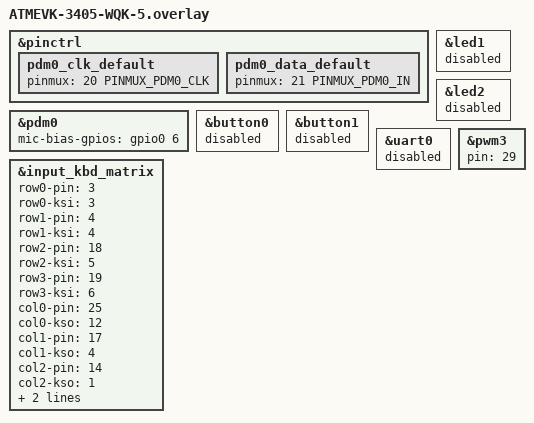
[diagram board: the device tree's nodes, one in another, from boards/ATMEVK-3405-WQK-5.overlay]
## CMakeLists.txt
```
# Copyright (c) 2026 Atmosic
#
# SPDX-License-Identifier: LicenseRef-Atmosic

cmake_minimum_required(VERSION 3.20.0)
set(EXTRA_DTC_OVERLAY_FILE "app.overlay")

find_package(Zephyr REQUIRED HINTS $ENV{ZEPHYR_BASE})
project(hid_remote)

include_directories(
  src
  src/bt
)

target_sources(app PRIVATE
  src/main.c
  src/rc_mmi.c
  src/rc_mmi_timer.c
  src/rc_input.c
  src/bt/rc_gap.c
  src/bt/rc_hids.c
)

if(CONFIG_RC_VOICE)
  target_sources(app PRIVATE src/rc_audio.c)
endif()

if(CONFIG_RC_LED)
  target_sources(app PRIVATE src/rc_led.c)
endif()

if(CONFIG_IR_NEC)
  target_sources(app PRIVATE src/rc_ir.c)
endif()

if(CONFIG_BT_IAS)
  target_sources(app PRIVATE src/rc_fmp.c)
endif()
```

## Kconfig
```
# Copyright (c) 2026 Atmosic
#
# SPDX-License-Identifier: LicenseRef-Atmosic

module = HID_REMOTE
module-str = hid_remote
source "subsys/logging/Kconfig.template.log_config"

config RC_VOICE
	bool "RC voice pipeline (ATVV + optional DMIC)"
	select ATM_ATVV
	select AUDIO
	select AUDIO_DMIC
	select AUDIO_ADPCM_ENC
	imply DMIC_ATM
	help
	  Enable the ATVV BLE voice profile with IMA ADPCM encoding.
	  DMIC_ATM is implied (not selected) because it has a devicetree
	  dependency (DT_HAS_ATMOSIC_ATM_PDM_ENABLED) that is satisfied by
	  the pdm0 node enabled in app.overlay under CONFIG_RC_VOICE.

if RC_VOICE

choice RC_ATVV_ASST_MODEL
	prompt "Assistant interaction model"
	default RC_ATVV_ASST_MODEL_ON_REQUEST
	help
	  Selects which "Assistant" button interaction model this remote
	  implements (Google Voice over BLE spec 1.0 §4.5). PTT/HTT require
	  CONFIG_ATVV_SPEC_V1_0 — v0.4e only defines On-request.

config RC_ATVV_ASST_MODEL_ON_REQUEST
	bool "On-request (legacy) — host decides when to open the mic"
	help
	  Mandatory baseline model, supported by all remotes. Mic button
	  press sends START_SEARCH; the host decides whether to open the
	  microphone via MIC_OPEN.

config RC_ATVV_ASST_MODEL_PTT
	bool "Press-to-Talk"
	depends on ATVV_SPEC_V1_0
	help
	  The remote opens the mic (AUDIO_START, reason=PTT) on Assistant
	  button press without waiting for MIC_OPEN. This implementation
	  closes it (AUDIO_STOP, reason=OTHER) on button release, since a
	  single button offers no separate "stop" gesture and the spec does
	  not define a dedicated reason code for a locally-initiated PTT
	  stop. The host may still end the session early via MIC_CLOSE.

config RC_ATVV_ASST_MODEL_HTT
	bool "Hold-to-Talk"
	depends on ATVV_SPEC_V1_0
	help
	  The remote opens the mic (AUDIO_START, reason=HTT) while the
	  Assistant button is held and closes it (AUDIO_STOP,
	  reason=HTT_RELEASE) on release, without waiting for MIC_OPEN, per
	  spec v1.0 §4.5.3. The host may still end the session early via
	  MIC_CLOSE.

endchoice

choice RC_ATVV_AUDIO_RATE
	prompt "Preferred ATVV audio sample rate"
	default RC_ATVV_AUDIO_RATE_16KHZ if ATVV_SPEC_V1_0
	default RC_ATVV_AUDIO_RATE_8KHZ
	depends on RC_VOICE
	help
	  Selects the sample rate and codec used when starting an ATVV audio
	  stream. The v1.0 capability response advertises both ADPCM 8 kHz and
	  16 kHz.

config RC_ATVV_AUDIO_RATE_8KHZ
	bool "8 kHz ADPCM"

config RC_ATVV_AUDIO_RATE_16KHZ
	bool "16 kHz ADPCM"
	depends on ATVV_SPEC_V1_0

endchoice

config RC_PDM_DEBUG
	bool "PDM-only debug mode"
	depends on RC_VOICE
	help
	  Debug mode for testing the PDM → ADPCM pipeline. When enabled,
	  pressing the key at row 0, col 1 in IDLE state starts audio
	  streaming directly (bypassing ATVV). Pressing the same key again
	  stops streaming and returns to IDLE.

choice LOG_MODE
	default LOG_MODE_IMMEDIATE if RC_PDM_DEBUG
endchoice

endif # RC_VOICE

config RC_LED
	bool "RC LED status indicator"
	default y if $(dt_alias_enabled,led0)
	depends on GPIO
	help
	  Enable LED blink patterns for pairing, reconnecting, and FMP alert
	  indication. Requires a ``led0`` GPIO alias in the board devicetree.
	  A build-time assertion will fire if this option is enabled but the
	  alias is absent.

config RC_IDLE_TIMEOUT_CS
	int "Idle disconnect timeout (centiseconds)"
	default 60000
	help
	  Disconnect after this many centiseconds of BLE inactivity while HID
	  is ready. Default 60000 cs = 600 s (10 minutes).

config RC_READY_TIMEOUT_CS
	int "HID ready watchdog timeout (centiseconds)"
	default 3000
	help
	  If HID does not become ready within this time after connection,
	  the connection is dropped. Default 3000 cs = 30 s.

config RC_HIB_DELAY_CS
	int "Hibernate delay after MMI idle (centiseconds)"
	default 1000
	help
	  Delay before entering hibernate once the MMI reaches idle state.
	  Default 1000 cs = 10 s.

config RC_AUDIO_STREAM_TIMEOUT_CS
	int "Audio Transfer Timeout (centiseconds)"
	default 3000
	depends on RC_VOICE
	help
	  Maximum duration of a single ATVV audio stream, per spec v1.0 §4.6.1
	  "Audio Transfer Timeout" (recommended 15-60 seconds). When this timeout
	  expires, the remote sends AUDIO_STOP (reason=TIMEOUT) and stops
	  streaming to prevent battery drain if the host fails to send MIC_CLOSE.
	  The host can extend the session by sending MIC_EXTEND (v1.0) before
	  expiry. Default 3000 cs = 30 s.

config RC_ADV_INTERVAL_MIN
	hex "Advertising interval minimum (units of 625 us)"
	default 0x0040
	help
	  Minimum advertising interval. Default 0x0040 = 40 ms.

config RC_ADV_INTERVAL_MAX
	hex "Advertising interval maximum (units of 625 us)"
	default 0x0040
	help
	  Maximum advertising interval. Default 0x0040 = 40 ms.

config RC_ADV0_DURATION_MS
	int "Reconnect advertising duration (ms)"
	default 30000
	help
	  Duration of the reconnect advertising window.

config RC_ADV1_DURATION_MS
	int "Pairing advertising duration (ms)"
	default 30000
	help
	  Duration of undirected pairing advertising window. Default 30000 ms.

source "Kconfig.zephyr"
```

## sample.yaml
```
# Copyright (c) 2026 Atmosic
#
# SPDX-License-Identifier: LicenseRef-Atmosic

sample:
  description: BLE HID Remote Controller sample
  name: BLE HID Remote Controller sample
common:
  sysbuild: true
  harness: console
  harness_config:
    type: one_line
    regex:
      - "rc_gap: Advertising Start"
  tags:
    - bluetooth
    - hid_remote
  depends_on:
    - hid_remote
tests:
  applications.hid_remote.atm: {}
  applications.hid_remote.atm.mcuboot.ota:
    tags:
      - mcuboot
    extra_args:
      - SB_CONFIG_BOOTLOADER_MCUBOOT=y
      - SB_CONFIG_BOOT_SIGNATURE_TYPE_ECDSA_P256=y
      - SB_CONFIG_MCUBOOT_MODE_SWAP_SCRATCH=y
      - SB_ATM_DTS_EXTRA_CPPFLAGS="-DATM_MCUBOOT_SWAP_WITH_OFFSET=0"
      - EXTRA_CONF_FILE="basic_ota_bt.conf"
```

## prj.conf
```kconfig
# Copyright (c) 2026 Atmosic
#
# SPDX-License-Identifier: LicenseRef-Atmosic

# BT core
CONFIG_BT=y
CONFIG_BT_SMP=y
CONFIG_BT_PERIPHERAL=y
CONFIG_BT_EXT_ADV=y
CONFIG_BT_EXT_ADV_MAX_ADV_SET=3
CONFIG_BT_ID_MAX=1
CONFIG_BT_MAX_PAIRED=2
CONFIG_BT_MAX_CONN=3
CONFIG_BT_KEYS_OVERWRITE_OLDEST=y

# Hibernation-retained pairing-mode marker
CONFIG_RETAINED_MEM=y

# Enable GATT client so the peripheral can initiate an MTU exchange when the
# host supports it. ATVV v1.0 sends one 128-byte notification per audio frame.
CONFIG_BT_GATT_CLIENT=y
CONFIG_BT_L2CAP_TX_MTU=146
CONFIG_BT_BUF_ACL_TX_SIZE=146
CONFIG_BT_BUF_ACL_RX_SIZE=146
CONFIG_BT_BUF_ACL_TX_COUNT=10
CONFIG_BT_ATT_TX_COUNT=20
CONFIG_BT_BUF_EVT_RX_COUNT=11
CONFIG_RC_PDM_DEBUG=n
CONFIG_ATM_DMIC_CAPTURE_ON_RISING=y

# Connection parameter preferences
CONFIG_BT_PERIPHERAL_PREF_MIN_INT=6
CONFIG_BT_PERIPHERAL_PREF_MAX_INT=12
CONFIG_BT_PERIPHERAL_PREF_LATENCY=99
CONFIG_BT_PERIPHERAL_PREF_TIMEOUT=400

# DIS
CONFIG_BT_DIS=y
CONFIG_BT_DIS_PNP=y
CONFIG_BT_DIS_MANUF_NAME_STR="Atmosic Tech."
CONFIG_BT_DIS_PNP_VID_SRC=2
CONFIG_BT_DIS_PNP_VID=0x045E
CONFIG_BT_DIS_PNP_PID=0x0050
CONFIG_BT_DIS_PNP_VER=0x0100

# BAS
CONFIG_BT_BAS=y

# Device identity
CONFIG_BT_DEVICE_NAME="Atmosic RC"
CONFIG_BT_DEVICE_APPEARANCE=384

# Stack sizes
CONFIG_MAIN_STACK_SIZE=2048
CONFIG_SYSTEM_WORKQUEUE_STACK_SIZE=2048
CONFIG_STACK_SENTINEL=y

# Settings / NVS
CONFIG_BT_SETTINGS=y
CONFIG_SETTINGS=y
CONFIG_NVS=y
CONFIG_FLASH=y
CONFIG_FLASH_MAP=y
CONFIG_FLASH_PAGE_LAYOUT=y

# Input subsystem
CONFIG_INPUT=y

# SMF (MMI + GAP state machine)
CONFIG_SMF=y

# Vendor API commands
CONFIG_ATM_VENDOR_API=y
CONFIG_VND_API_SET_ADV_TX_POWER=y
CONFIG_VND_API_SET_CON_TX_POWER=y

# HOGP
CONFIG_ATM_HOGP=y

# FMP — Find Me Profile
CONFIG_BT_IAS=y

# VOICE / AUDIO
CONFIG_RC_VOICE=y

# IR/NEC blaster
CONFIG_IR_NEC=y

# Log
CONFIG_LOG=y
```

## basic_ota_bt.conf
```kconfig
# Copyright (c) 2026 Atmosic
#
# SPDX-License-Identifier: LicenseRef-Atmosic

# Enable MCUmgr with image and OS management command groups
CONFIG_ATM_MCUMGR=y

# Enable MCUmgr Bluetooth transport with encryption (level 2)
CONFIG_MCUMGR_TRANSPORT_BT=y
CONFIG_MCUMGR_TRANSPORT_BT_PERM_RW_ENCRYPT=y
```

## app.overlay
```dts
/*
 * Copyright (c) 2026 Atmosic
 *
 * SPDX-License-Identifier: LicenseRef-Atmosic
 */

&wdog0 {
	status = "okay";
};

&pwm3 {
	status = "okay";
};

/ {
	ir_blaster: ir_blaster {
		compatible = "atmosic,ir-nec";
		pwms = <&pwm3 3 0 0>;
	};
};

&pdm0 {
	status = "okay";
	pinctrl-0 = <&pdm0_clk_default &pdm0_data_default>;
	pinctrl-names = "default";
	clock-frequency = <1000000>;
};
```

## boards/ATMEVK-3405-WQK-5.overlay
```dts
/*
 * Copyright (c) 2022-2026 Atmosic
 *
 * SPDX-License-Identifier: LicenseRef-Atmosic
 */

&pinctrl {
	pdm0_clk_default: pdm0_clk_default {
		pinmux = <20 PINMUX_PDM0_CLK>;
	};

	pdm0_data_default: pdm0_data_default {
		pinmux = <21 PINMUX_PDM0_IN>;
	};
};

&pdm0 {
	/* P6 is freed by disabling the board LED below. */
	mic-bias-gpios = <&gpio0 6 GPIO_ACTIVE_HIGH>;
};

&led1 {
	status = "disabled";
};

&led2 {
	status = "disabled";
};

&button0 {
	status = "disabled";
};

&button1 {
	status = "disabled";
};

&uart0 {
	status = "disabled";
};

&pwm3 {
	pin = <29>;
};

&input_kbd_matrix {
	row0-pin = <3>;
	row0-ksi = <3>;
	row1-pin = <4>;
	row1-ksi = <4>;
	row2-pin = <18>;
	row2-ksi = <5>;
	row3-pin = <19>;
	row3-ksi = <6>;
	col0-pin = <25>;
	col0-kso = <12>;
	col1-pin = <17>;
	col1-kso = <4>;
	col2-pin = <14>;
	col2-kso = <1>;
	col3-pin = <22>;
	col3-kso = <9>;
	status = "okay";
};
```

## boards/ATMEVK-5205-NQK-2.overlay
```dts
/*
 * Copyright (c) 2026 Atmosic
 *
 * SPDX-License-Identifier: LicenseRef-Atmosic
 */

&pinctrl {
	pdm0_clk_default: pdm0_clk_default {
		pinmux = <30 PINMUX_PDM0_CLK>;
	};

	pdm0_data_default: pdm0_data_default {
		pinmux = <13 PINMUX_PDM0_IN>;
	};
};

&pdm0 {
	mic-bias-gpios = <&gpio2 9 GPIO_ACTIVE_HIGH>;
};

&input_kbd_matrix {
	row0-pin = <26>;
	row0-ksi = <0>;
	row1-pin = <39>;
	row1-ksi = <8>;
	row2-pin = <37>;
	row2-ksi = <6>;
	row3-pin = <38>;
	row3-ksi = <7>;
	col0-pin = <14>;
	col0-kso = <1>;
	col1-pin = <15>;
	col1-kso = <2>;
	col2-pin = <16>;
	col2-kso = <3>;
	col3-pin = <17>;
	col3-kso = <4>;
	status = "okay";
};
```

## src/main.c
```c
/*
 * Copyright (c) 2026 Atmosic
 *
 * SPDX-License-Identifier: LicenseRef-Atmosic
 */

#include <zephyr/kernel.h>
#include <zephyr/drivers/watchdog.h>
#include <zephyr/logging/log.h>
#include <zephyr/pm/pm.h>

#include "rc_mmi.h"

LOG_MODULE_REGISTER(main, CONFIG_HID_REMOTE_LOG_LEVEL);

#define SLEEP_TIME        K_SECONDS(3)
#define WDT_MIN_WINDOW_MS 0
#define WDT_MAX_WINDOW_MS 5000
#define WDT_FEED_INTERVAL K_SECONDS(2)

struct device const *wdog_dev = DEVICE_DT_GET(DT_ALIAS(watchdog0));
static int wdt_channel_id;

/*
 * Feed the watchdog periodically, independent of PM state transitions. While
 * connected (e.g. during pairing) the SoC can stay awake for longer than the
 * watchdog window with no PM transition, so relying on PM notifiers alone
 * starves the watchdog and triggers a spurious SoC reset mid-pairing.
 */
static void wdog_feed_work_handler(struct k_work *work)
{
	struct k_work_delayable *dwork = k_work_delayable_from_work(work);

	wdt_feed(wdog_dev, wdt_channel_id);
	k_work_reschedule(dwork, WDT_FEED_INTERVAL);
}

static K_WORK_DELAYABLE_DEFINE(wdog_feed_work, wdog_feed_work_handler);

#ifdef CONFIG_PM
static void wdog_poke(enum pm_state state)
{
	wdt_feed(wdog_dev, wdt_channel_id);
}

static struct pm_notifier notifier = {
	.state_entry = wdog_poke,
	.state_exit = wdog_poke,
};
#endif

int main(void)
{
	struct wdt_timeout_cfg wdt_config = {
		.flags = WDT_FLAG_RESET_SOC,
		.window.min = WDT_MIN_WINDOW_MS,
		.window.max = WDT_MAX_WINDOW_MS,
		.callback = NULL,
	};

	wdt_channel_id = wdt_install_timeout(wdog_dev, &wdt_config);
	if (wdt_channel_id < 0) {
		LOG_ERR("Watchdog install error: %d", wdt_channel_id);
		return 1;
	}

	int ret = wdt_setup(wdog_dev, 0);
	if (ret < 0) {
		LOG_ERR("Watchdog setup error: %d", ret);
		return 1;
	}

	rc_mmi_init();

	/* Keep feeding the watchdog while awake, regardless of PM activity. */
	k_work_reschedule(&wdog_feed_work, WDT_FEED_INTERVAL);

#ifdef CONFIG_PM
	pm_notifier_register(&notifier);
#else
	while (true) {
		k_sleep(SLEEP_TIME);
		wdt_feed(wdog_dev, wdt_channel_id);
	}
#endif

	return 0;
}
```

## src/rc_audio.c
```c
/*
 * Copyright (c) 2026 Atmosic
 *
 * SPDX-License-Identifier: LicenseRef-Atmosic
 */

#include "rc_audio.h"
#include "rc_mmi.h"
#include "atvv.h"

#include <zephyr/kernel.h>
#include <zephyr/logging/log.h>
#include <zephyr/logging/log_ctrl.h>
#include <zephyr/sys/byteorder.h>
#include <zephyr/settings/settings.h>

#if defined(CONFIG_DMIC_ATM)
#include "adpcm_enc.h"
#include <zephyr/audio/dmic.h>
#endif

LOG_MODULE_REGISTER(rc_audio, CONFIG_HID_REMOTE_LOG_LEVEL);

#define RC_ATVV_SETTINGS_KEY "atvv/cfg"

static bool atvv_configured;

#if defined(CONFIG_DMIC_ATM)
/* DMIC to ADPCM to ATVV streaming pipeline. */
/* The PDM block contains 32 samples; one ATVV frame contains 256 samples. */
#define PP_BUFFER_WORDS 16
#define PP_SAMPLES      (PP_BUFFER_WORDS * 2)
#if defined(CONFIG_RC_ATVV_AUDIO_RATE_16KHZ)
#define AUDIO_SAMPLE_RATE 16000
#else
#define AUDIO_SAMPLE_RATE 8000
#endif
#define PCM_WIDTH_BITS        16
#define BLOCK_SIZE            (PP_SAMPLES * sizeof(int16_t)) /* 64 bytes */
#define PCM_SAMPLES_PER_FRAME (ATVV_AUDIO_DATA_SIZE * 2)
#define NUM_SLAB_BLOCKS       ((PCM_SAMPLES_PER_FRAME + PP_SAMPLES - 1) / PP_SAMPLES + 4)

K_MEM_SLAB_DEFINE_STATIC(audio_slab, BLOCK_SIZE, NUM_SLAB_BLOCKS, 4);

static const struct device *dmic_dev = DEVICE_DT_GET(DT_NODELABEL(pdm0));

static volatile bool streaming_active;
static uint16_t frame_seq;
static struct k_sem stream_sem;

#define AUDIO_STACK_SIZE 2048
static K_THREAD_STACK_DEFINE(audio_stack, AUDIO_STACK_SIZE);
static struct k_thread audio_tid;

/* Send AUDIO_SYNC periodically, including frame 0. */
#define SYNC_PERIOD_FRAMES 20

#ifdef CONFIG_RC_PDM_DEBUG
/* Optional debug capture buffers. */
#define PDM_DBG_DUMP_FRAMES 125
static int16_t pdm_dbg_pcm[PDM_DBG_DUMP_FRAMES * PCM_SAMPLES_PER_FRAME];
static uint8_t pdm_dbg_adpcm[PDM_DBG_DUMP_FRAMES * ATVV_AUDIO_DATA_SIZE];
static uint32_t pdm_dbg_frame_cnt;
#endif
#endif /* CONFIG_DMIC_ATM */

static int atvv_cfg_set(const char *key, size_t len, settings_read_cb read_cb, void *cb_arg)
{
	ARG_UNUSED(key);
	if (len != sizeof(atvv_configured)) {
		return -EINVAL;
	}
	int rc = read_cb(cb_arg, &atvv_configured, sizeof(atvv_configured));
	return rc < 0 ? rc : 0;
}

SETTINGS_STATIC_HANDLER_DEFINE(rc_atvv, "atvv", NULL, atvv_cfg_set, NULL, NULL);

static void atvv_save_configured(bool configured)
{
	atvv_configured = configured;
	settings_save_one(RC_ATVV_SETTINGS_KEY, &atvv_configured, sizeof(atvv_configured));
}

/* ATVV callbacks. */

#if defined(CONFIG_ATVV_SPEC_V1_0)

#if defined(CONFIG_RC_ATVV_AUDIO_RATE_16KHZ)
#define RC_ATVV_CODEC_USED ATVV_CODEC_ADPCM_16K
#else
#define RC_ATVV_CODEC_USED ATVV_CODEC_ADPCM_8K
#endif
#define RC_ATVV_CODECS_SUPPORTED ATVV_CODEC_ADPCM_8K_16K

/* Assistant interaction model reported in CAPS_RESP. */
#if defined(CONFIG_RC_ATVV_ASST_MODEL_HTT)
#define RC_ATVV_MODEL ATVV_ASST_MODEL_HTT
#elif defined(CONFIG_RC_ATVV_ASST_MODEL_PTT)
#define RC_ATVV_MODEL ATVV_ASST_MODEL_PTT
#else /* CONFIG_RC_ATVV_ASST_MODEL_ON_REQUEST */
#define RC_ATVV_MODEL ATVV_ASST_MODEL_ON_REQUEST
#endif

/* Current ATVV stream ID. */
static uint8_t current_stream_id;
/* True while an ATVV audio session is active. */
static bool session_active;

#if defined(CONFIG_RC_ATVV_ASST_MODEL_PTT) || defined(CONFIG_RC_ATVV_ASST_MODEL_HTT)
/* Allocate PTT/HTT stream IDs. */
static uint8_t alloc_stream_id(void)
{
	static uint8_t next_id = 0x01;
	uint8_t id = next_id;

	next_id = (next_id >= 0x80) ? 0x01 : (uint8_t)(next_id + 1);
	return id;
}
#endif

#endif /* CONFIG_ATVV_SPEC_V1_0 */

/* Audio transfer timeout. */

static void audio_timeout_handler(struct k_work *work);
static K_WORK_DELAYABLE_DEFINE(audio_timeout_work, audio_timeout_handler);

/* Start or reset the audio timeout. */
static void audio_timeout_start(void)
{
	k_work_reschedule(&audio_timeout_work, K_MSEC(CONFIG_RC_AUDIO_STREAM_TIMEOUT_CS * 10));
	LOG_DBG("Audio Transfer Timeout started/reset (%u cs)", CONFIG_RC_AUDIO_STREAM_TIMEOUT_CS);
}

static void audio_timeout_stop(void)
{
	k_work_cancel_delayable(&audio_timeout_work);
}

static void audio_timeout_handler(struct k_work *work)
{
	LOG_WRN("Audio Transfer Timeout expired — stopping stream");
	rc_audio_stream_stop();
	rc_mmi_run_event(MMI_OP_CLOSE_MIC);
#if defined(CONFIG_ATVV_SPEC_V1_0)
	atvv_send_audio_stop(ATVV_AUDIO_STOP_REASON_TIMEOUT);
	session_active = false;
#else
	atvv_send_audio_stop();
#endif
}

static void atvv_tx_recv_cb(uint8_t cmd, uint8_t const *data, uint16_t len)
{
	switch (cmd) {
	case ATVV_TX_GET_CAPS:
		/* Host requests capabilities — respond with CAPS_RESP */
		LOG_INF("GET_CAPS");
#if defined(CONFIG_ATVV_SPEC_V1_0)
		const struct atvv_caps_resp_params caps = {
			.version = ATVV_VERSION_V1_0,
			.codecs = RC_ATVV_CODECS_SUPPORTED,
			.asst_model = RC_ATVV_MODEL,
			.frame_size = ATVV_FRAME_SIZE,
		};
#else
		const struct atvv_caps_resp_params caps = {
			.version = ATVV_VERSION_V0_4,
			.codecs = ATVV_CODEC_ADPCM_8K,
			.asst_model = 0,
			.frame_size = ATVV_FRAME_SIZE,
		};
#endif
		atvv_send_caps_resp(&caps);
		atvv_save_configured(true);
		break;
	case ATVV_TX_MIC_OPEN: {
#if defined(CONFIG_ATVV_SPEC_V1_0)
		if (atvv_get_state() != ATVV_STATE_READY || len != 1) {
			LOG_WRN("MIC_OPEN ignored: state=%d len=%u", atvv_get_state(), len);
			break;
		}

		/* v1.0 MIC_OPEN contains mic_mode; the codec comes from configuration. */
		uint8_t mic_mode = (len >= 1) ? data[0] : ATVV_MIC_MODE_PLAYBACK;

		LOG_INF("MIC_OPEN mic_mode=0x%02x codec=0x%02x", mic_mode,
			(unsigned)RC_ATVV_CODEC_USED);

		if (session_active) {
			if (current_stream_id != ATVV_STREAM_ID_MIC_OPEN) {
				LOG_WRN("MIC_OPEN rejected: PTT/HTT stream ongoing");
				atvv_send_mic_open_error(ATVV_ERR_PTT_HTT_ONGOING);
			} else {
				LOG_DBG("MIC_OPEN ignored: stream already active");
			}
			break;
		}
		current_stream_id = ATVV_STREAM_ID_MIC_OPEN;
		session_active = true;
		atvv_send_audio_start(ATVV_AUDIO_START_REASON_MIC_OPEN, RC_ATVV_CODEC_USED,
				      current_stream_id);
		audio_timeout_start();
#else
		if (atvv_get_state() != ATVV_STATE_READY || len != 2) {
			LOG_WRN("MIC_OPEN ignored: state=%d len=%u", atvv_get_state(), len);
			break;
		}

		/* v0.4e MIC_OPEN payload: codec_used(2, big-endian) */
		uint16_t codec_used = (len >= 2) ? sys_get_be16(data) : ATVV_CODEC_ADPCM_8K;

		LOG_INF("MIC_OPEN codec=0x%04x", codec_used);
		if (codec_used != ATVV_CODEC_ADPCM_8K) {
			LOG_WRN("Unsupported codec 0x%04x", codec_used);
			atvv_send_mic_open_error(ATVV_ERR_INVALID_CODEC);
			break;
		}
		atvv_send_audio_start();
		audio_timeout_start();
#endif
		rc_mmi_run_event(MMI_OP_OPEN_MIC);
		break;
	}
	case ATVV_TX_MIC_CLOSE:
#if defined(CONFIG_ATVV_SPEC_V1_0)
	{
		if (!session_active) {
			LOG_DBG("MIC_CLOSE ignored: no active session");
			break;
		}

		/* v1.0 MIC_CLOSE contains the stream ID. */
		uint8_t req_id = (len >= 1) ? data[0] : ATVV_STREAM_ID_ANY;

		LOG_INF("MIC_CLOSE stream_id=0x%02x (active=0x%02x)", req_id, current_stream_id);
		if (req_id != ATVV_STREAM_ID_ANY && req_id != current_stream_id) {
			LOG_DBG("MIC_CLOSE stream_id mismatch — ignored");
			break;
		}
		audio_timeout_stop();
		rc_audio_stream_stop();
		atvv_send_audio_stop(ATVV_AUDIO_STOP_REASON_MIC_CLOSE);
		session_active = false;
	}
#else
		LOG_INF("MIC_CLOSE");
		audio_timeout_stop();
		rc_audio_stream_stop();
		atvv_send_audio_stop();
#endif
		rc_mmi_run_event(MMI_OP_CLOSE_MIC);
		break;
#if defined(CONFIG_ATVV_SPEC_V1_0)
	case ATVV_TX_MIC_EXTEND:
		/* Keep the audio timeout alive. */
		LOG_DBG("MIC_EXTEND stream_id=0x%02x", (len >= 1) ? data[0] : 0xFF);
		if (session_active) {
			audio_timeout_start(); /* reset the timer */
		}
		break;
#endif
	default:
		LOG_DBG("ATVV TX cmd 0x%02x (unhandled)", cmd);
		break;
	}
}

static void atvv_state_changed_cb(atvv_state_t state)
{
	LOG_INF("ATVV state -> %d", state);
	switch (state) {
	case ATVV_STATE_READY:
		rc_mmi_run_event(MMI_OP_ATVV_READY);
		break;
	case ATVV_STATE_IDLE:
#if defined(CONFIG_ATVV_SPEC_V1_0)
		audio_timeout_stop();
		session_active = false;
		current_stream_id = ATVV_STREAM_ID_MIC_OPEN;
#endif
		atvv_save_configured(false);
		rc_mmi_run_event(MMI_OP_ATVV_UNREADY);
		break;
	case ATVV_STATE_ENABLED:
		rc_mmi_run_event(MMI_OP_ATVV_UNREADY);
		break;
	}
}

static atvv_cb_t const atvv_cbs = {
	.tx_recv = atvv_tx_recv_cb,
	.state_changed = atvv_state_changed_cb,
};

bool rc_audio_atvv_was_configured(void)
{
	return atvv_configured;
}

#if defined(CONFIG_DMIC_ATM)
static void audio_thread_fn(void *p1, void *p2, void *p3)
{
	static int16_t pcm_acc[PCM_SAMPLES_PER_FRAME];
	static int16_t block_pcm[PP_SAMPLES];
	size_t pcm_samples = 0;
	bool mtu_error = false;

	/* Reset the encoder at the start of each session. */
	adpcm_reset();

#ifdef CONFIG_RC_PDM_DEBUG
	pdm_dbg_frame_cnt = 0;
#endif

	while (streaming_active) {
		void *buf = NULL;
		size_t size = 0;
		int ret = dmic_read(dmic_dev, 0, &buf, &size, 200);
		if (ret) {
			if (ret != -EAGAIN) {
				LOG_ERR("dmic_read err %d", ret);
			}
			continue;
		}

		size_t sample_count = MIN(size / sizeof(int16_t), ARRAY_SIZE(block_pcm));
		memcpy(block_pcm, buf, sample_count * sizeof(int16_t));
		k_mem_slab_free(&audio_slab, buf);

		for (size_t i = 0; i < sample_count; i++) {
			pcm_acc[pcm_samples++] = block_pcm[i];
			if (pcm_samples < PCM_SAMPLES_PER_FRAME) {
				continue;
			}

			/* Capture the encoder state before this frame. */
			struct atvv_audio_frame frame = {};
			uint8_t predictor_idx = 0;
			int32_t predictor_val = adpcm_get_index(&predictor_idx);
			uint16_t this_frame_no = frame_seq;
			bool need_sync = (this_frame_no % SYNC_PERIOD_FRAMES) == 0;

			/* Encode one frame. */
			adpcm_encode_buf(pcm_acc, frame.val, PCM_SAMPLES_PER_FRAME);
			frame_seq++;

#ifdef CONFIG_RC_PDM_DEBUG
			if (pdm_dbg_frame_cnt < PDM_DBG_DUMP_FRAMES) {
				memcpy(&pdm_dbg_pcm[pdm_dbg_frame_cnt * PCM_SAMPLES_PER_FRAME],
				       pcm_acc, PCM_SAMPLES_PER_FRAME * sizeof(int16_t));
				memcpy(&pdm_dbg_adpcm[pdm_dbg_frame_cnt * ATVV_AUDIO_DATA_SIZE],
				       frame.val, ATVV_AUDIO_DATA_SIZE);
				pdm_dbg_frame_cnt++;
			}
#endif

			/* Continue remaining samples in the next frame. */
			pcm_samples = 0;

#if defined(CONFIG_ATVV_SPEC_V1_0)
			/* v1.0 sends state in periodic AUDIO_SYNC messages. */
			if (need_sync) {
				/* Count logical audio notifications. */
				uint16_t notify_seq = this_frame_no * ATVV_AUDIO_NOTIFY_COUNT;
				int sync_ret =
					atvv_send_audio_sync(RC_ATVV_CODEC_USED, notify_seq,
							     (int16_t)predictor_val, predictor_idx);
				if (sync_ret) {
					LOG_WRN("ATVV AUDIO_SYNC failed: %d, seq=%u", sync_ret,
						notify_seq);
				}
			}
			int send_ret = atvv_send_audio_frame(&frame);
			if (send_ret == -EMSGSIZE) {
				LOG_ERR("ATVV audio stopped: insufficient ATT MTU");
				streaming_active = false;
				mtu_error = true;
			} else if (send_ret) {
				LOG_WRN("ATVV audio packet dropped (%d), frame=%u", send_ret,
					this_frame_no);
			}
#else
			/* v0.4e carries state in the frame header. */
			frame.idx = predictor_idx;
			frame.prevp = sys_cpu_to_be16((int16_t)predictor_val);
			frame.seqn = sys_cpu_to_be16(this_frame_no);
			frame.padding = 0x00;

			int send_ret = atvv_send_audio_frame(&frame);
			if (send_ret == -EMSGSIZE) {
				LOG_ERR("ATVV audio stopped: insufficient ATT MTU");
				streaming_active = false;
				mtu_error = true;
			} else if (send_ret) {
				LOG_DBG("ATVV send dropped (%d)", send_ret);
			}
			if (need_sync) {
				atvv_send_audio_sync(this_frame_no);
			}
#endif
		}
	}

	dmic_trigger(dmic_dev, DMIC_TRIGGER_STOP);
	LOG_INF("audio thread stopped");
	if (mtu_error) {
#if defined(CONFIG_ATVV_SPEC_V1_0)
		atvv_send_audio_stop(ATVV_AUDIO_STOP_REASON_OTHER);
#else
		atvv_send_audio_stop();
#endif
		rc_mmi_run_event(MMI_OP_CLOSE_MIC);
	}

#ifdef CONFIG_RC_PDM_DEBUG
	/* Serialize optional debug output. */
	LOG_PANIC();
	LOG_INF("=== PDM DBG dump: %u frames ===", pdm_dbg_frame_cnt);
	for (uint32_t i = 0; i < pdm_dbg_frame_cnt; i++) {
		LOG_HEXDUMP_INF(&pdm_dbg_pcm[i * PCM_SAMPLES_PER_FRAME],
				PCM_SAMPLES_PER_FRAME * sizeof(int16_t), "PCM");
	}
	LOG_INF("=== PDM DBG dump end ===");
	LOG_INF("=== ADPCM DBG dump: %u frames, %u bytes/frame ===", pdm_dbg_frame_cnt,
		ATVV_AUDIO_DATA_SIZE);
	for (uint32_t i = 0; i < pdm_dbg_frame_cnt; i++) {
		LOG_HEXDUMP_INF(&pdm_dbg_adpcm[i * ATVV_AUDIO_DATA_SIZE], ATVV_AUDIO_DATA_SIZE,
				"ADPCM");
	}
	LOG_INF("=== ADPCM DBG dump end ===");
#endif
}

static int dmic_start_capture(void)
{
	struct pcm_stream_cfg stream = {
		.pcm_rate = AUDIO_SAMPLE_RATE,
		.pcm_width = PCM_WIDTH_BITS,
		.block_size = BLOCK_SIZE,
		.mem_slab = &audio_slab,
	};
	struct dmic_cfg cfg = {
		.io =
			{
				.min_pdm_clk_freq = 1000000,
				.max_pdm_clk_freq = 4000000,
				.min_pdm_clk_dc = 40,
				.max_pdm_clk_dc = 60,
			},
		.streams = &stream,
		.channel =
			{
				.req_num_chan = 1,
				.req_num_streams = 1,
			},
	};

	int ret = dmic_configure(dmic_dev, &cfg);
	if (ret) {
		LOG_ERR("dmic_configure err %d", ret);
		return ret;
	}

	ret = dmic_trigger(dmic_dev, DMIC_TRIGGER_START);
	if (ret) {
		LOG_ERR("dmic_trigger START err %d", ret);
	}
	return ret;
}

#endif /* CONFIG_DMIC_ATM */

/* ── Public API ──────────────────────────────────────────────────────────── */

void rc_audio_init(void)
{
	settings_load_subtree("atvv");
	LOG_INF("ATVV prev configured: %d", atvv_configured);
	atvv_init(&atvv_cbs);
#if defined(CONFIG_DMIC_ATM)
	if (!device_is_ready(dmic_dev)) {
		LOG_ERR("DMIC device not ready");
		return;
	}
	k_sem_init(&stream_sem, 0, 1);
	LOG_INF("rc_audio init: DMIC+ATVV ready");
#else
	LOG_INF("rc_audio init: ATVV only (no DMIC)");
#endif
}

void rc_audio_stream_start(void)
{
#if defined(CONFIG_DMIC_ATM)
	if (streaming_active) {
		return;
	}
	frame_seq = 0;
	streaming_active = true;

	int ret = dmic_start_capture();
	if (ret) {
		streaming_active = false;
		rc_mmi_run_event(MMI_OP_CLOSE_MIC);
		return;
	}

	k_thread_create(&audio_tid, audio_stack, K_THREAD_STACK_SIZEOF(audio_stack),
			audio_thread_fn, NULL, NULL, NULL, K_PRIO_PREEMPT(7), 0, K_NO_WAIT);
	k_thread_name_set(&audio_tid, "rc_audio");
	LOG_INF("audio stream started");
#else
	LOG_INF("rc_audio_stream_start: DMIC not enabled");
#endif
}

void rc_audio_stream_stop(void)
{
#if defined(CONFIG_DMIC_ATM)
	if (!streaming_active) {
		return;
	}
	streaming_active = false;
	/* audio_thread_fn checks streaming_active and will call dmic_trigger(STOP) */
	LOG_INF("audio stream stop requested");
#endif
}

void rc_audio_start_search(void)
{
	if (atvv_get_state() != ATVV_STATE_READY) {
		LOG_WRN("ATVV not ready, ignoring start_search");
		return;
	}

#if defined(CONFIG_RC_ATVV_ASST_MODEL_PTT) || defined(CONFIG_RC_ATVV_ASST_MODEL_HTT)
	/* PTT/HTT: remote unilaterally opens the mic on button press,
	 * without waiting for a host MIC_OPEN (v1.0 §4.5.2 / §4.5.3). */
	if (session_active) {
		LOG_DBG("start_search: session already active");
		return;
	}
	current_stream_id = alloc_stream_id();
	session_active = true;
#if defined(CONFIG_RC_ATVV_ASST_MODEL_HTT)
	atvv_send_audio_start(ATVV_AUDIO_START_REASON_HTT, RC_ATVV_CODEC_USED, current_stream_id);
#else
	atvv_send_audio_start(ATVV_AUDIO_START_REASON_PTT, RC_ATVV_CODEC_USED, current_stream_id);
#endif
	audio_timeout_start();
	LOG_INF("PTT/HTT stream opened (stream_id=0x%02x)", current_stream_id);
	rc_mmi_run_event(MMI_OP_OPEN_MIC);
#else
	/* On-request (mandatory baseline): remote sends START_SEARCH on mic
	 * button press. Host responds with MIC_OPEN to begin streaming. */
	LOG_INF("START_SEARCH");
	atvv_send_ctl(ATVV_CTL_SEARCH_START, NULL, 0);
#endif
}

void rc_audio_stop_search(void)
{
#if defined(CONFIG_RC_ATVV_ASST_MODEL_PTT)
	/* PTT: stop the locally initiated stream on button release. */
	if (!session_active) {
		return;
	}
	audio_timeout_stop();
	rc_audio_stream_stop();
	rc_mmi_run_event(MMI_OP_CLOSE_MIC);
	atvv_send_audio_stop(ATVV_AUDIO_STOP_REASON_OTHER);
	session_active = false;
	LOG_INF("PTT release stopped");
#elif defined(CONFIG_RC_ATVV_ASST_MODEL_HTT)
	/* HTT: button release stops the stream immediately, remote-initiated
	 * (v1.0 §4.5.3), without waiting for MIC_CLOSE. */
	if (!session_active) {
		return;
	}
	audio_timeout_stop();
	rc_audio_stream_stop();
	rc_mmi_run_event(MMI_OP_CLOSE_MIC);
	atvv_send_audio_stop(ATVV_AUDIO_STOP_REASON_HTT_RELEASE);
	session_active = false;
	LOG_INF("HTT release stopped");
#else
	/* On-request: button-initiated stop mirrors a host-driven MIC_CLOSE
	 * from the remote's own release of the mic key. */
	audio_timeout_stop();
	rc_audio_stream_stop();
	rc_mmi_run_event(MMI_OP_CLOSE_MIC);
#if defined(CONFIG_ATVV_SPEC_V1_0)
	atvv_send_audio_stop(ATVV_AUDIO_STOP_REASON_MIC_CLOSE);
	session_active = false;
	current_stream_id = ATVV_STREAM_ID_MIC_OPEN;
#else
	atvv_send_audio_stop();
#endif
	LOG_INF("search stopped");
#endif
}

void rc_audio_dpad_select(void)
{
	atvv_state_t s = atvv_get_state();

	if (s == ATVV_STATE_READY || s == ATVV_STATE_ENABLED) {
		LOG_DBG("DPAD_SELECT");
		atvv_send_ctl(ATVV_CTL_DPAD_SELECT, NULL, 0);
	}
}
```

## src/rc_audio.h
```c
/*
 * Copyright (c) 2026 Atmosic
 *
 * SPDX-License-Identifier: LicenseRef-Atmosic
 */

#pragma once

#include <stdbool.h>

/** @brief Initialise the audio subsystem (ATVV + optional DMIC). */
void rc_audio_init(void);

/** @brief Start the audio capture and streaming pipeline. */
void rc_audio_stream_start(void);

/** @brief Stop the audio capture and streaming pipeline. */
void rc_audio_stream_stop(void);

/**
 * @brief Start voice search / streaming on Assistant (MIC) button press.
 *
 * Behaviour depends on CONFIG_RC_ATVV_ASST_MODEL:
 *   - On-request : sends ATVV_CTL_SEARCH_START; host replies with MIC_OPEN.
 *   - PTT / HTT  : remote itself sends AUDIO_START and begins streaming,
 *                  without waiting for MIC_OPEN (requires CONFIG_ATVV_SPEC_V1_0).
 * No-op if ATVV is not ready, or if a session is already active.
 */
void rc_audio_start_search(void);

/**
 * @brief Returns true if ATVV was successfully configured in a previous session.
 *
 * Persisted via Settings subsystem.
 * Use to skip CAPS negotiation on reconnect when host is known to support ATVV.
 */
bool rc_audio_atvv_was_configured(void);

/**
 * @brief Stop voice search on Assistant (MIC) button release.
 *
 * Behaviour depends on CONFIG_RC_ATVV_ASST_MODEL:
 *   - On-request : stops local capture and sends AUDIO_STOP (reason
 *                  ATVV_AUDIO_STOP_REASON_MIC_CLOSE on CONFIG_ATVV_SPEC_V1_0;
 *                  no payload on CONFIG_ATVV_SPEC_V0_4).
 *   - HTT        : stops local capture and sends AUDIO_STOP (reason
 *                  ATVV_AUDIO_STOP_REASON_HTT_RELEASE) immediately.
 *   - PTT        : stops local capture and sends AUDIO_STOP (reason
 *                  ATVV_AUDIO_STOP_REASON_OTHER) on button release.
 */
void rc_audio_stop_search(void);

/**
 * @brief Notify host of a D-pad select (OK button) during voice session.
 *
 * Sends ATVV_CTL_DPAD_SELECT to the host. Should be called on OK key press
 * when ATVV is in READY or streaming state.
 */
void rc_audio_dpad_select(void);
```

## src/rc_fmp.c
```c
/*
 * Copyright (c) 2026 Atmosic
 *
 * SPDX-License-Identifier: LicenseRef-Atmosic
 */

#include <zephyr/bluetooth/services/ias.h>
#include <zephyr/logging/log.h>

#include "rc_fmp.h"
#include "rc_led.h"

LOG_MODULE_REGISTER(rc_fmp, CONFIG_HID_REMOTE_LOG_LEVEL);

/* ── IAS callbacks ──────────────────────────────────────────────────────── */

static void rc_fmp_no_alert(void)
{
	LOG_INF("FMP: no alert");
	rc_led_set(RC_LED_OFF);
}

static void rc_fmp_mild_alert(void)
{
	LOG_INF("FMP: mild alert");
	rc_led_set(RC_LED_FMP_MILD);
}

static void rc_fmp_high_alert(void)
{
	LOG_INF("FMP: high alert");
	rc_led_set(RC_LED_FMP_HIGH);
}

BT_IAS_CB_DEFINE(rc_fmp_cb) = {
	.no_alert = rc_fmp_no_alert,
	.mild_alert = rc_fmp_mild_alert,
	.high_alert = rc_fmp_high_alert,
};

/* ── Init ───────────────────────────────────────────────────────────────── */

void rc_fmp_init(void)
{
	LOG_INF("FMP init");
}
```

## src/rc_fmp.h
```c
/*
 * Copyright (c) 2026 Atmosic
 *
 * SPDX-License-Identifier: LicenseRef-Atmosic
 */

#pragma once

/** @brief Initialise the FMP / IAS server. */
void rc_fmp_init(void);
```

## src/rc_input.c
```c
/*
 * Copyright (c) 2026 Atmosic
 *
 * SPDX-License-Identifier: LicenseRef-Atmosic
 */

#include <zephyr/kernel.h>
#include <zephyr/sys/reboot.h>
#include <zephyr/input/input.h>
#include <zephyr/device.h>
#include <zephyr/logging/log.h>

#ifdef CONFIG_PM
#include <zephyr/pm/pm.h>
#include <zephyr/pm/policy.h>
#endif

#include "rc_input.h"
#include "rc_mmi.h"
#include "rc_vkey.h"
#include "bt/rc_gap.h"
#include "bt/rc_hids.h"
#include "rc_led.h"
#ifdef CONFIG_IR_NEC
#include "rc_ir.h"
#endif
#ifdef CONFIG_RC_VOICE
#include "rc_audio.h"
#endif

LOG_MODULE_REGISTER(rc_input, CONFIG_HID_REMOTE_LOG_LEVEL);

#define INPUT_KBD_MATRIX_NODE DT_NODELABEL(input_kbd_matrix)

#define KEY_BUF_SIZE 16
static struct {
	uint8_t row;
	uint8_t col;
	bool pressed;
} keybuf[KEY_BUF_SIZE];
static uint8_t keybuf_offset;
static bool state_reconnected;

/* Key positions from rc_vkey.h consumer_map */
#define COMBO_HOME_ROW 1
#define COMBO_HOME_COL 2
#define COMBO_BACK_ROW 1
#define COMBO_BACK_COL 1
#define COMBO_OK_ROW   2
#define COMBO_OK_COL   0
#define COMBO_VOLU_ROW 2
#define COMBO_VOLU_COL 3

enum combo_id {
	COMBO_PAIRING,  /* HOME + BACK — enter pairing mode */
	COMBO_DEL_BOND, /* OK + VOLU  — delete all bonds    */
	COMBO_NUM,
};

enum combo_key_slot {
	COMBO_KEY_A,
	COMBO_KEY_B,
	COMBO_KEY_COUNT,
};

#define KBD_KEY_ROW_CMP(row, key)       ((row) == (key))
#define KBD_KEY_COLUMN_CMP(column, key) ((column) == (key))
#define KBD_KEY_CMP(row, row_key, column, column_key)                                              \
	(KBD_KEY_ROW_CMP(row, row_key) && KBD_KEY_COLUMN_CMP(column, column_key))

/* Per-combo descriptor */
struct combo_desc {
	uint8_t row_a, col_a;
	uint8_t row_b, col_b;
	const char *name;
};

static const struct combo_desc combo_descs[COMBO_NUM] = {
	[COMBO_PAIRING] = {COMBO_HOME_ROW, COMBO_HOME_COL, COMBO_BACK_ROW, COMBO_BACK_COL,
			   "HOME+BACK"},
	[COMBO_DEL_BOND] = {COMBO_OK_ROW, COMBO_OK_COL, COMBO_VOLU_ROW, COMBO_VOLU_COL, "OK+VOLU"},
};

/* Per-key press state indexed by combo ID and key slot. */
static bool combo_key_state[COMBO_NUM][COMBO_KEY_COUNT];

/* One work item per combo so the action runs outside the input callback. */
static struct k_work_delayable combo_works[COMBO_NUM];
static bool combo_active[COMBO_NUM];

static rc_input_led_restore_cb_t led_restore_cb;

static void combo_action_exec(enum combo_id id)
{
	LOG_INF("Combo %s fired", combo_descs[id].name);
	rc_hogp_send_release_all();

	switch (id) {
	case COMBO_PAIRING:
		LOG_INF("Entering pairing mode until cold boot");
		rc_gap_set_force_pairing();
		return;
	case COMBO_DEL_BOND:
		rc_gap_remove_all_bond();
		break;
	default:
		break;
	}

	rc_led_set(RC_LED_OFF);
	k_sleep(K_MSEC(1000));
	sys_reboot(SYS_REBOOT_COLD);
}

/* Each combo has its own handler to avoid shared-variable race on cancel. */
static void combo_pairing_handler(struct k_work *work)
{
	combo_active[COMBO_PAIRING] = false;
	combo_action_exec(COMBO_PAIRING);
}

static void combo_del_bond_handler(struct k_work *work)
{
	combo_active[COMBO_DEL_BOND] = false;
	combo_action_exec(COMBO_DEL_BOND);
}

static k_work_handler_t const combo_handlers[COMBO_NUM] = {
	[COMBO_PAIRING] = combo_pairing_handler,
	[COMBO_DEL_BOND] = combo_del_bond_handler,
};

/* Returns true when at least one combo is currently active (both keys pressed),
 * meaning the caller should suppress normal HID processing for this key event.
 * A single combo key pressed alone is NOT suppressed — only the combination. */
static bool combo_key_update(uint32_t row, uint32_t col, bool pressed)
{
	/* Update press state for every key that belongs to any combo */
	bool relevant = false;

	for (int i = 0; i < COMBO_NUM; i++) {
		const struct combo_desc *d = &combo_descs[i];

		if (KBD_KEY_CMP(row, d->row_a, col, d->col_a)) {
			combo_key_state[i][COMBO_KEY_A] = pressed;
			relevant = true;
		} else if (KBD_KEY_CMP(row, d->row_b, col, d->col_b)) {
			combo_key_state[i][COMBO_KEY_B] = pressed;
			relevant = true;
		}
	}

	if (!relevant) {
		return false;
	}

	/* Activate / cancel each combo independently */
	bool any_active = false;

	for (int i = 0; i < COMBO_NUM; i++) {
		bool both = combo_key_state[i][COMBO_KEY_A] && combo_key_state[i][COMBO_KEY_B];

		if (!combo_active[i] && both) {
			combo_active[i] = true;
			LOG_INF("Combo detected: %s", combo_descs[i].name);
			k_work_reschedule(&combo_works[i], K_NO_WAIT);
		}

		if (combo_active[i]) {
			any_active = true;
		}
	}

	if (any_active) {
		rc_led_set(RC_LED_ON);
	} else if (led_restore_cb) {
		led_restore_cb();
	} else {
		rc_led_set(RC_LED_OFF);
	}

	/* Suppress HID once a combo is detected. */
	return any_active;
}

static void handle_key_hid_ready(uint32_t row, uint32_t col, bool pressed, int state)
{
	uint16_t csm = rc_vkey_get_consumer_code(row, col);

	if (!csm) {
		rc_hogp_send_key_report(row, col, pressed);
		return;
	}

	rc_hogp_send_consumer_report(pressed ? csm : 0);

#ifdef CONFIG_RC_VOICE
	if (csm == HID_CSM_MIC) {
		if (pressed && state == MMI_S_HID_READY) {
			rc_audio_start_search();
		} else if (!pressed && state == MMI_S_STREAMING) {
			rc_audio_stop_search();
		}
		return;
	}
	if (pressed && csm == HID_CSM_OK) {
		rc_audio_dpad_select();
	}
#endif /* CONFIG_RC_VOICE */
}

void rc_input_handle_key(uint32_t row, uint32_t col, bool pressed)
{
#ifdef CONFIG_IR_NEC
	/* IR is independent of BLE state — send/stop on any key event. */
	uint16_t ir_addr;
	uint8_t ir_cmd;

	if (rc_vkey_get_ir_code(row, col, &ir_addr, &ir_cmd)) {
		pressed ? rc_ir_send(ir_addr, ir_cmd) : rc_ir_stop();
	}
#endif

	/* Combo key detection (pairing / delete bond) — works in all states.
	 * combo_key_update() returns true if this key belongs to an active combo;
	 * in that case suppress the normal HID path so the host never sees
	 * the individual key events while the combo is being held. */
	if (combo_key_update(row, col, pressed)) {
		return;
	}

#if defined(CONFIG_PM) && !defined(CONFIG_APP_BATT)
	if (pressed) {
		pm_policy_state_lock_get(PM_STATE_SOFT_OFF, PM_ALL_SUBSTATES);
	} else {
		if (pm_policy_state_lock_is_active(PM_STATE_SOFT_OFF, PM_ALL_SUBSTATES)) {
			pm_policy_state_lock_put(PM_STATE_SOFT_OFF, PM_ALL_SUBSTATES);
		}
	}
#endif

	int state = rc_mmi_get_state();

#ifdef CONFIG_RC_PDM_DEBUG
	/* Debug: row0/col1 toggles PDM streaming, bypassing ATVV/BLE.
	 * Intercept in all states except DISCONNING to avoid conflict. */
	if (row == 0 && col == 1 && state != MMI_S_DISCONNING) {
		if (pressed) {
			if (state != MMI_S_STREAMING) {
				LOG_INF("DBG: start PDM streaming (from state %d)", state);
				rc_mmi_run_event(MMI_OP_OPEN_MIC);
			} else {
				LOG_INF("DBG: stop PDM streaming");
				rc_mmi_run_event(MMI_OP_CLOSE_MIC);
			}
		}
		return;
	}
#endif

	if (state == MMI_S_IDLE) {
		rc_gap_discoverable(true);
	}

	if (state < MMI_S_HID_READY) {
		uint16_t csm = rc_vkey_get_consumer_code(row, col);

		if (csm == HID_CSM_MIC) {
			return;
		}
		if (keybuf_offset < KEY_BUF_SIZE) {
			keybuf[keybuf_offset].row = (uint8_t)row;
			keybuf[keybuf_offset].col = (uint8_t)col;
			keybuf[keybuf_offset].pressed = pressed;
			keybuf_offset++;
		} else {
			LOG_DBG("keybuf overflow");
		}
		return;
	}

	handle_key_hid_ready(row, col, pressed, state);
}

void rc_input_flush_keybuf(void)
{
	if (!state_reconnected) {
		keybuf_offset = 0;
		return;
	}

	for (uint8_t i = 0; i < keybuf_offset; i++) {
		uint32_t r = keybuf[i].row;
		uint32_t c = keybuf[i].col;
		bool pressed = keybuf[i].pressed;
		uint16_t csm = rc_vkey_get_consumer_code(r, c);

		if (csm) {
			rc_hogp_send_consumer_report(pressed ? csm : 0);
		} else {
			rc_hogp_send_key_report(r, c, pressed);
		}
	}
	state_reconnected = false;
	keybuf_offset = 0;
}

bool rc_input_keybuf_pending(void)
{
	return keybuf_offset > 0;
}

void rc_input_set_reconnected(bool reconnected)
{
	state_reconnected = reconnected;
}

static void input_callback(struct input_event *evt, void *user_data)
{
	static uint32_t row, col;

	switch (evt->code) {
	case INPUT_ABS_X:
		col = evt->value;
		break;
	case INPUT_ABS_Y:
		row = evt->value;
		break;
	case INPUT_BTN_TOUCH:
		if (evt->sync) {
			rc_input_handle_key(row, col, (bool)evt->value);
		}
		break;
	}
}

INPUT_CALLBACK_DEFINE(DEVICE_DT_GET(INPUT_KBD_MATRIX_NODE), input_callback, NULL);

void rc_input_init(rc_input_led_restore_cb_t cb)
{
	led_restore_cb = cb;
	for (int i = 0; i < COMBO_NUM; i++) {
		k_work_init_delayable(&combo_works[i], combo_handlers[i]);
	}
}
```

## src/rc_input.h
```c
/*
 * Copyright (c) 2026 Atmosic
 *
 * SPDX-License-Identifier: LicenseRef-Atmosic
 */

#pragma once

#include <stdint.h>
#include <stdbool.h>

/**
 * @brief Callback to restore the LED to the current MMI-state-appropriate mode.
 *
 * Provided by rc_mmi.c and called by the combo engine when a combo is
 * cancelled so the LED reverts to whatever the state machine dictates.
 */
typedef void (*rc_input_led_restore_cb_t)(void);

/**
 * @brief Initialise the input/combo subsystem.
 *
 * Must be called once after rc_led_init().
 * The INPUT_CALLBACK_DEFINE listener is registered at build time; this call
 * only initialises the combo work items.
 *
 * @param led_restore_cb  Callback invoked when an active combo is cancelled.
 */
void rc_input_init(rc_input_led_restore_cb_t led_restore_cb);

/**
 * @brief Dispatch a decoded key event into the input pipeline.
 *
 * Handles IR, combo detection, PM locks, key buffering, and HID reports.
 * Called from the INPUT_CALLBACK_DEFINE listener inside rc_input.c.
 * Also exposed so rc_mmi.c can replay buffered keys on reconnect without
 * duplicating the HID send logic.
 *
 * @param row      Matrix row of the key.
 * @param col      Matrix column of the key.
 * @param pressed  true = pressed, false = released.
 */
void rc_input_handle_key(uint32_t row, uint32_t col, bool pressed);

/**
 * @brief Flush buffered key events accumulated before HID was ready.
 *
 * Called by rc_mmi.c when transitioning to MMI_S_HID_READY.
 */
void rc_input_flush_keybuf(void);

/**
 * @brief Return true if any buffered keys are pending.
 */
bool rc_input_keybuf_pending(void);

/**
 * @brief Update the "state reconnected" flag used when flushing the keybuf.
 *
 * Set to true on CONNECTED, cleared after flush.
 */
void rc_input_set_reconnected(bool reconnected);
```

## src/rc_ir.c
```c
/*
 * Copyright (c) 2026 Atmosic
 *
 * SPDX-License-Identifier: LicenseRef-Atmosic
 */

#include <zephyr/kernel.h>
#include <zephyr/device.h>
#include <zephyr/devicetree.h>
#include <zephyr/logging/log.h>
#include <zephyr/drivers/ir_nec.h>

#include "rc_ir.h"

LOG_MODULE_REGISTER(rc_ir, CONFIG_HID_REMOTE_LOG_LEVEL);

static const struct device *const ir_dev = DEVICE_DT_GET(DT_NODELABEL(ir_blaster));

void rc_ir_init(void)
{
	if (!device_is_ready(ir_dev)) {
		LOG_WRN("IR blaster not ready");
	}
}

void rc_ir_send(uint16_t addr, uint8_t cmd)
{
	if (!device_is_ready(ir_dev)) {
		return;
	}
	/* If a previous repeat sequence is still finishing (DMA in flight
	 * after rc_ir_stop), force-stop it so the new key press is not
	 * silently dropped with -EBUSY. */
	if (ir_nec_busy(ir_dev)) {
		ir_nec_stop(ir_dev);
		/* Allow fifo_done_cb to clear busy before retrying */
		k_msleep(2);
	}
	int ret = ir_nec_send_repeat(ir_dev, addr, cmd, NULL);
	if (ret && ret != -EBUSY) {
		LOG_WRN("IR send failed: %d", ret);
	}
}

void rc_ir_stop(void)
{
	if (!device_is_ready(ir_dev)) {
		return;
	}
	ir_nec_stop(ir_dev);
}
```

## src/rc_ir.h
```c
/*
 * Copyright (c) 2026 Atmosic
 *
 * SPDX-License-Identifier: LicenseRef-Atmosic
 */

#pragma once

#include <stdint.h>

/** @brief Verify the IR blaster device is ready.  Call once at boot. */
void rc_ir_init(void);

/**
 * @brief Begin transmitting NEC frames for the given address/command.
 *
 * Sends one full NEC frame then repeats every 110 ms until rc_ir_stop() is
 * called.  If the blaster is already busy the call is silently ignored.
 *
 * @param addr NEC device address (8-bit standard or 16-bit extended).
 * @param cmd  NEC command byte.
 */
void rc_ir_send(uint16_t addr, uint8_t cmd);

/** @brief Stop an ongoing NEC repeat sequence. */
void rc_ir_stop(void);
```

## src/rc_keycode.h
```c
/*
 * Copyright (c) 2026 Atmosic
 *
 * SPDX-License-Identifier: LicenseRef-Atmosic
 */

#pragma once

#include <zephyr/usb/class/hid.h>

/*
 *   - HID_KEY_*  : USB HID Keyboard usage page (0x07)
 *   - HID_CSM_*  : USB HID Consumer Control usage page (0x0C)
 *   - IR_*       : NEC IR address and command codes (ATMRC_3330e_HSC)
 */

/* ── Keyboard usage IDs not defined in <zephyr/usb/class/hid.h> ─────────── */

#define HID_KEY_NONE       0x00
#define HID_KEY_MUTE       0x7F
#define HID_KEY_VOLUMEUP   0x80
#define HID_KEY_VOLUMEDOWN 0x81

/* Modifier keycodes (usage page 0x07, range 0xe0–0xe7) */
#define HID_KEY_LEFTCTRL   0xe0
#define HID_KEY_LEFTSHIFT  0xe1
#define HID_KEY_LEFTALT    0xe2
#define HID_KEY_LEFTMETA   0xe3
#define HID_KEY_RIGHTCTRL  0xe4
#define HID_KEY_RIGHTSHIFT 0xe5
#define HID_KEY_RIGHTALT   0xe6
#define HID_KEY_RIGHTMETA  0xe7

/* ── HID Consumer Control usage IDs (Usage Page 0x0C) ───────────────────── */

#define HID_CSM_POWER      0x0030
#define HID_CSM_PLAY_PAUSE 0x00CD
#define HID_CSM_BW         0x00B6 /* Scan Previous Track  — BT_BW   */
#define HID_CSM_FW         0x00B5 /* Scan Next Track      — BT_FW   */
#define HID_CSM_MUTE       0x00E2 /*                      — BT_MUTE */
#define HID_CSM_VOLUMEUP   0x00E9 /*                      — BT_VOLU */
#define HID_CSM_VOLUMEDOWN 0x00EA /*                      — BT_VOLD */
#define HID_CSM_MIC        0x0221 /* AC Search            — BT_MIC / BT_ASST */
#define HID_CSM_HOME       0x0223 /*                      — BT_HOME */
#define HID_CSM_BACK       0x0224 /*                      — BT_BACK */
#define HID_CSM_INPUT      0x01BB /* AC Select Input      — BT_INPUT */
#define HID_CSM_OK         0x0041 /*                      — BT_OK / BT_CENTER */
#define HID_CSM_UP         0x0042 /*                      — BT_UP   */
#define HID_CSM_DOWN       0x0043 /*                      — BT_DOWN */
#define HID_CSM_LEFT       0x0044 /*                      — BT_LEFT */
#define HID_CSM_RIGHT      0x0045 /*                      — BT_RIGHT */
#define HID_CSM_SETT       0x0096 /* AL Consumer Ctrl Cfg — BT_SETT */
#define HID_CSM_GUIDE      0x008D /* AL Media Select Home — BT_GUIDE */
#define HID_CSM_LIVE       0x0089 /* AL Media Select TV   — BT_LIVE */
#define HID_CSM_CNLU       0x009C /* Channel Up           — BT_CNLU */
#define HID_CSM_CNLD       0x009D /* Channel Down         — BT_CNLD */
#define HID_CSM_YOUTUBE    0x0077 /*                      — BT_YOUTUBE */
#define HID_CSM_NETFLIX    0x0078 /*                      — BT_NETFLIX */
#define HID_CSM_APP03      0x0079 /*                      — BT_APP03 */
#define HID_CSM_APP04      0x007A /*                      — BT_APP04 */

/* ── HID Keyboard usage IDs (Usage Page 0x07) ───────────────────────────── */

#define HID_KEY_MENU 0x76 /* Application          — BT_MENU  */

/* ── NEC IR codes (default board, addr = 0x80) ──────────────────────────── */

#ifdef CONFIG_IR_NEC
#define IR_ADDR  0x80
#define IR_POWER 0x46
#define IR_UP    0x52
#define IR_LEFT  0x06
#define IR_OK    0x0F
#define IR_RIGHT 0x1A
#define IR_MENU  0x07
#define IR_DOWN  0x13
#define IR_BACK  0x1B
#define IR_HOME  0x17
#define IR_VOLU  0x16
#define IR_VOLD  0x15
#endif /* CONFIG_IR_NEC */
```

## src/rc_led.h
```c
/*
 * Copyright (c) 2026 Atmosic
 *
 * SPDX-License-Identifier: LicenseRef-Atmosic
 */

#pragma once

/** @brief LED operating modes. */
enum rc_led_mode {
	RC_LED_OFF,          /**< LED off (connected / idle / stopped) */
	RC_LED_ON,           /**< LED solid on (combo key hold indication) */
	RC_LED_PAIRING,      /**< 100 ms blink — pairing advertising */
	RC_LED_RECONNECTING, /**< 250 ms blink — reconnect advertising */
	RC_LED_FMP_MILD,     /**< 500 ms blink — FMP mild alert */
	RC_LED_FMP_HIGH,     /**< 125 ms blink — FMP high alert */
};

/** @brief Initialise the LED GPIO and blink work queue item. */
void rc_led_init(void);

/**
 * @brief Set the LED to the given mode.
 * @param mode One of the @ref rc_led_mode values.
 */
void rc_led_set(enum rc_led_mode mode);
```
